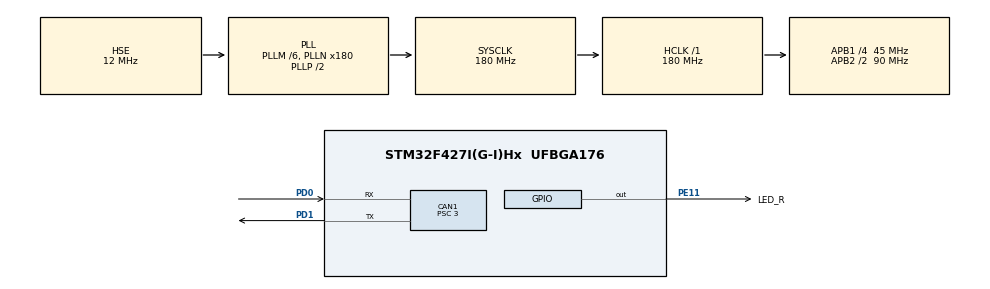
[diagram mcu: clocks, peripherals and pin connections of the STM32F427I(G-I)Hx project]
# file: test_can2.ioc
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CAN1.ABOM=ENABLE
CAN1.BS1=CAN_BS1_11TQ
CAN1.BS2=CAN_BS2_3TQ
CAN1.CalculateBaudRate=1000000
CAN1.CalculateTimeBit=1000
CAN1.CalculateTimeQuantum=66.66666666666666
CAN1.Mode=CAN_MODE_NORMAL
CAN1.Prescaler=3
Mcu.Family=STM32F4
Mcu.Name=STM32F427I(G-I)Hx
Mcu.Package=UFBGA176
NVIC.CAN1_RX0_IRQn=true\:0\:0\:false\:false\:true\:true\:true\:true
NVIC.CAN1_RX1_IRQn=true\:0\:0\:false\:false\:true\:true\:true\:true
NVIC.CAN1_SCE_IRQn=true\:0\:0\:false\:false\:true\:true\:true\:true
NVIC.CAN1_TX_IRQn=true\:0\:0\:false\:false\:true\:true\:true\:true
NVIC.PriorityGroup=NVIC_PRIORITYGROUP_4
PA13.Mode=Serial_Wire
PA13.Signal=SYS_JTMS-SWDIO
PA14.Mode=Serial_Wire
PA14.Signal=SYS_JTCK-SWCLK
PD0.Mode=CAN_Activate
PD0.Signal=CAN1_RX
PD1.Mode=CAN_Activate
PD1.Signal=CAN1_TX
PE11.GPIO_Label=LED_R
PE11.Signal=GPIO_Output
PH0/OSC_IN.Mode=HSE-External-Oscillator
PH0/OSC_IN.Signal=RCC_OSC_IN
PH1/OSC_OUT.Mode=HSE-External-Oscillator
PH1/OSC_OUT.Signal=RCC_OSC_OUT
ProjectManager.HeapSize=0x200
ProjectManager.StackSize=0x400
ProjectManager.TargetToolchain=STM32CubeIDE
RCC.48MHZClocksFreq_Value=90000000
RCC.AHBFreq_Value=180000000
RCC.APB1CLKDivider=RCC_HCLK_DIV4
RCC.APB1Freq_Value=45000000
RCC.APB1TimFreq_Value=90000000
RCC.APB2CLKDivider=RCC_HCLK_DIV2
RCC.APB2Freq_Value=90000000
RCC.APB2TimFreq_Value=180000000
RCC.CortexFreq_Value=180000000
RCC.HCLKFreq_Value=180000000
RCC.HSE_VALUE=12000000
RCC.HSI_VALUE=16000000
RCC.LSE_VALUE=32768
RCC.PLLM=6
RCC.PLLN=180
RCC.PLLSourceVirtual=RCC_PLLSOURCE_HSE
RCC.SYSCLKFreq_VALUE=180000000
RCC.SYSCLKSource=RCC_SYSCLKSOURCE_PLLCLK
RCC.VCOOutputFreq_Value=360000000
board=custom

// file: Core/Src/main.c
/* USER CODE BEGIN Header */
/**
  ******************************************************************************
  * @file           : main.c
  * @brief          : Main program body
  ******************************************************************************
  * @attention
  *
  * Copyright (c) 2024 STMicroelectronics.
  * All rights reserved.
  *
  * This software is licensed under terms that can be found in the LICENSE file
  * in the root directory of this software component.
  * If no LICENSE file comes with this software, it is provided AS-IS.
  *
  ******************************************************************************
  */
/* USER CODE END Header */
#include "main.h"
#include "can.h"
#include "gpio.h"

/* USER CODE BEGIN Includes */
//
// Created by 28672 on 24-10-12.
//

#include "stm32f4xx_hal_can.h"

/* USER CODE END Includes */

/* USER CODE BEGIN PV */
float linearMapping(int in_,int in_min,int in_max,float out_min,float out_max){
  float k = (out_max-out_min)/(float) (in_max - in_min);
  return out_min + (float) (in_ - in_min)*k;
}
struct M3508_Motor_v5 {
  float ratio_;           // 电机减�?�比
  float angle_fractional; // deg 输出端累计转动角度的小数部分
  float angle_integer;	// 角度的整数部�????
  float delta_angle_;     // deg 输出端新转动的角�????
  float ecd_angle_;       // deg 当前电机编码器角�????
  float last_ecd_angle_;  // deg 上次电机编码器角�????
  float delta_ecd_angle_; // deg 编码器端新转动的角度
  float rotate_speed_;    // dps 反馈转子转�??
  float current_;         // A   反馈转矩电流
  float temp_;            // °C  反馈电机温度
};
struct M3508_Motor_v5 motor = {3591.0/187,0,0,0,0,0,0,0,0,0};
void canRxMsgCallback_v5(const uint8_t rx_data[8]){
  motor.last_ecd_angle_ = motor.ecd_angle_;
  motor.ecd_angle_ = linearMapping(rx_data[0]<< 8 | rx_data[1],0,8191,0,360);
  motor.delta_ecd_angle_ = motor.ecd_angle_  - motor.last_ecd_angle_;
  motor.rotate_speed_ = rx_data[2]<< 8 | rx_data[3];
  motor.current_ = rx_data[4]<< 8 | rx_data[5];
  motor.temp_ = rx_data[6];
  motor.delta_angle_ = motor.delta_angle_ + motor.delta_ecd_angle_;

  motor.angle_fractional = motor.angle_fractional + motor.delta_ecd_angle_;
  motor.angle_integer = motor.angle_integer +  (int) motor.angle_fractional;
  motor.angle_fractional = motor.angle_fractional - (int) motor.angle_fractional;
}

CAN_TxHeaderTypeDef TxHeader;

/* USER CODE END PV */

void SystemClock_Config(void);

int main(void)
{

  /* MCU Configuration--------------------------------------------------------*/

  /* Reset of all peripherals, Initializes the Flash interface and the Systick. */
  HAL_Init();

  /* Configure the system clock */
  SystemClock_Config();

  /* Initialize all configured peripherals */
  MX_GPIO_Init();
  MX_CAN1_Init();

  /* Infinite loop */
  /* USER CODE BEGIN WHILE */
  CAN_FilterTypeDef sFilterConfig;
  sFilterConfig.FilterBank = 0; // 选择过滤器编�?????????
  sFilterConfig.FilterMode = CAN_FILTERMODE_IDMASK; // 使用掩码模式
  sFilterConfig.FilterScale = CAN_FILTERSCALE_32BIT; // 32位过�r���?????
  sFilterConfig.FilterIdHigh = 0x0000; // 设置滤波器ID高位（使�?????????0x0000为例�?????????
  sFilterConfig.FilterIdLow = 0x0000; // 设置滤波器ID低位
  sFilterConfig.FilterMaskIdHigh = 0x0000; // 设置掩码ID高位（使�?????????0x0000，这意味�?????????匹配�?????????有）
  sFilterConfig.FilterMaskIdLow = 0x0000; // 设置掩码ID低位
  sFilterConfig.FilterBank = 14;
  sFilterConfig.FilterFIFOAssignment = CAN_FILTER_FIFO0; // 将过滤器分配�????????? FIFO0
  sFilterConfig.FilterActivation = CAN_FILTER_ENABLE; // 启用过滤�?????????
  HAL_CAN_ConfigFilter(&hcan1,&sFilterConfig);
  HAL_CAN_Start(&hcan1);
  /* USER CODE BEGIN 2 */

  /* USER CODE END 2 */

  /* Infinite loop */
  /* USER CODE BEGIN WHILE */
  uint8_t TxMessage[8] = {0,0x90,0,0,0,0,0,0};
  while (1)
  {
		for(int i = 0;i<8;i++)
			TxMessage[i] += i;
    TxHeader.ExtId = 0;
    TxHeader.StdId = 0x200; // 标准 ID
    TxHeader.IDE = CAN_ID_STD; // 标准标识�????
    TxHeader.RTR = CAN_RTR_DATA; // 数据�????
    TxHeader.DLC = sizeof(TxMessage); // 数据长度
    TxHeader.TransmitGlobalTime = DISABLE;
    uint32_t TxMailbox;
    if(HAL_CAN_AddTxMessage(&hcan1,&TxHeader,TxMessage, &TxMailbox)!=HAL_OK)
    {
      HAL_GPIO_WritePin(LED_R_GPIO_Port,LED_R_Pin,1);
    }
    HAL_GPIO_WritePin(LED_R_GPIO_Port,LED_R_Pin,0);

    HAL_Delay(500);
    /* USER CODE END WHILE */

  }
}

void SystemClock_Config(void)
{
  RCC_OscInitTypeDef RCC_OscInitStruct = {0};
  RCC_ClkInitTypeDef RCC_ClkInitStruct = {0};

  /** Configure the main internal regulator output voltage
  */
  __HAL_RCC_PWR_CLK_ENABLE();
  __HAL_PWR_VOLTAGESCALING_CONFIG(PWR_REGULATOR_VOLTAGE_SCALE1);

  /** Initializes the RCC Oscillators according to the specified parameters
  * in the RCC_OscInitTypeDef structure.
  */
  RCC_OscInitStruct.OscillatorType = RCC_OSCILLATORTYPE_HSE;
  RCC_OscInitStruct.HSEState = RCC_HSE_ON;
  RCC_OscInitStruct.PLL.PLLState = RCC_PLL_ON;
  RCC_OscInitStruct.PLL.PLLSource = RCC_PLLSOURCE_HSE;
  RCC_OscInitStruct.PLL.PLLM = 6;
  RCC_OscInitStruct.PLL.PLLN = 180;
  RCC_OscInitStruct.PLL.PLLP = RCC_PLLP_DIV2;
  RCC_OscInitStruct.PLL.PLLQ = 4;
  if (HAL_RCC_OscConfig(&RCC_OscInitStruct) != HAL_OK)
  {
    Error_Handler();
  }

  /** Activate the Over-Drive mode
  */
  if (HAL_PWREx_EnableOverDrive() != HAL_OK)
  {
    Error_Handler();
  }

  /** Initializes the CPU, AHB and APB buses clocks
  */
  RCC_ClkInitStruct.ClockType = RCC_CLOCKTYPE_HCLK|RCC_CLOCKTYPE_SYSCLK
                              |RCC_CLOCKTYPE_PCLK1|RCC_CLOCKTYPE_PCLK2;
  RCC_ClkInitStruct.SYSCLKSource = RCC_SYSCLKSOURCE_PLLCLK;
  RCC_ClkInitStruct.AHBCLKDivider = RCC_SYSCLK_DIV1;
  RCC_ClkInitStruct.APB1CLKDivider = RCC_HCLK_DIV4;
  RCC_ClkInitStruct.APB2CLKDivider = RCC_HCLK_DIV2;

  if (HAL_RCC_ClockConfig(&RCC_ClkInitStruct, FLASH_LATENCY_5) != HAL_OK)
  {
    Error_Handler();
  }
}

void Error_Handler(void)
{
  __disable_irq();
  while (1)
  {
  }
}
